VERSION ""

NS_ :

BS_:

BU_: XXX

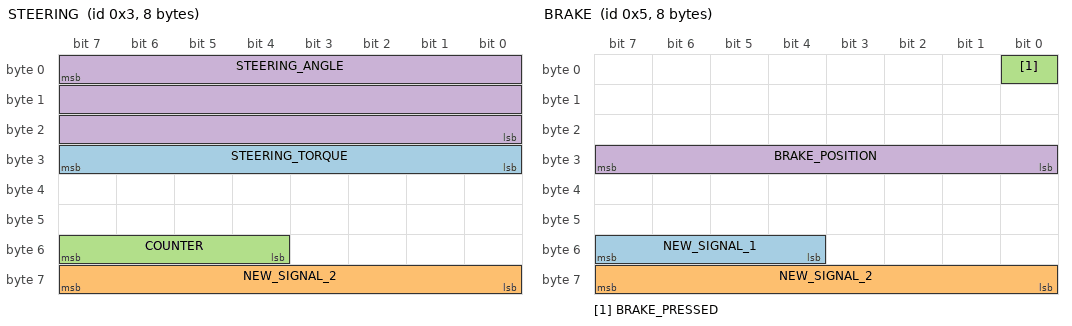
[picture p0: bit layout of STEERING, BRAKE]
BO_ 3 STEERING: 8 XXX
 SG_ STEERING_TORQUE : 31|8@0+ (1,0) [0|255] "" XXX
 SG_ NEW_SIGNAL_2 : 63|8@0+ (1,0) [0|255] "" XXX
 SG_ COUNTER : 55|4@0+ (1,0) [0|15] "" XXX
 SG_ STEERING_ANGLE : 7|24@0- (1,0) [0|4294967295] "" XXX

BO_ 5 BRAKE: 8 XXX
 SG_ NEW_SIGNAL_1 : 55|4@0+ (1,0) [0|15] "" XXX
 SG_ NEW_SIGNAL_2 : 63|8@0+ (1,0) [0|255] "" XXX
 SG_ BRAKE_PRESSED : 0|1@1+ (1,0) [0|17] "" XXX
 SG_ BRAKE_POSITION : 31|8@0+ (1,0) [0|65535] "" XXX

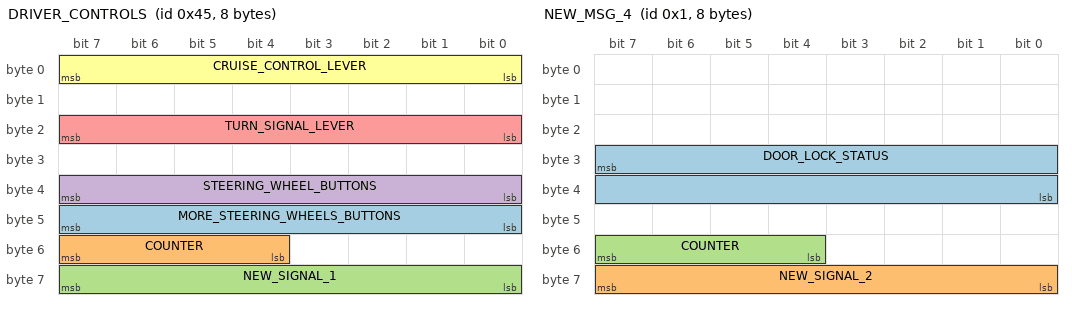
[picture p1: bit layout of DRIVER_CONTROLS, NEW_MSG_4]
BO_ 69 DRIVER_CONTROLS: 8 XXX
 SG_ MORE_STEERING_WHEELS_BUTTONS : 40|8@1+ (1,0) [0|255] "" XXX
 SG_ COUNTER : 55|4@0+ (1,0) [0|15] "" XXX
 SG_ NEW_SIGNAL_1 : 63|8@0+ (1,0) [0|255] "" XXX
 SG_ STEERING_WHEEL_BUTTONS : 32|8@1+ (1,0) [0|255] "4 directional, 2 volume control & 2 phone buttons" XXX
 SG_ TURN_SIGNAL_LEVER : 16|8@1+ (1,0) [0|255] "" XXX
 SG_ CRUISE_CONTROL_LEVER : 7|8@0+ (1,0) [0|255] "enable, cancel, increment/decrement by 1mph, increment/decrement by 5mph" XXX

BO_ 1 NEW_MSG_4: 8 XXX
 SG_ DOOR_LOCK_STATUS : 31|16@0+ (1,0) [0|65535] "" XXX
 SG_ NEW_SIGNAL_2 : 63|8@0+ (1,0) [0|255] "" XXX
 SG_ COUNTER : 55|4@0+ (1,0) [0|15] "" XXX

BO_ 581 NEW_MSG_5: 8 XXX
 SG_ COUNTER : 55|4@0+ (1,0) [0|15] "" XXX

BO_ 513 NEW_MSG_6: 8 XXX
 SG_ COUNTER : 55|4@0+ (1,0) [0|15] "" XXX
 SG_ NEW_SIGNAL_2 : 56|8@1+ (1,0) [0|255] "" XXX

BO_ 261 NEW_MSG_1: 8 XXX
 SG_ COUNTER : 55|4@0+ (1,0) [0|15] "" XXX

BO_ 925 NEW_MSG_2: 8 XXX
 SG_ COUNTER : 62|4@0+ (1,0) [0|15] "" XXX

CM_ SG_ 5 BRAKE_PRESSED "appears to be boolean (brake pressed)";
CM_ SG_ 69 MORE_STEERING_WHEELS_BUTTONS "back, ok, voice assistance, and mute buttons";
CM_ SG_ 69 TURN_SIGNAL_LEVER "momentary left, momentary right, toggle left, toggle right, momentary high beam, toggle high beam";
